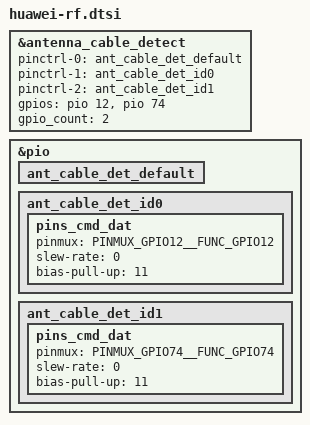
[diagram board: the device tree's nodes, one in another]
&antenna_cable_detect {
	pinctrl-names = "default", "id0", "id1";
	pinctrl-0 = <&ant_cable_det_default>;
	pinctrl-1 = <&ant_cable_det_id0>;
	pinctrl-2 = <&ant_cable_det_id1>;
	gpios = <&pio 12 0 >,
			<&pio 74 0 >;
	gpio_count = <2>;
};

&pio {
	ant_cable_det_default: ant_cable_det_default {
	};

	ant_cable_det_id0: ant_cable_det_id0 {
		pins_cmd_dat {
			pinmux = <PINMUX_GPIO12__FUNC_GPIO12>;
			slew-rate = <0>;
			bias-pull-up = <11>;
		};
	};
	ant_cable_det_id1: ant_cable_det_id1 {
		pins_cmd_dat {
			pinmux = <PINMUX_GPIO74__FUNC_GPIO74>;
			slew-rate = <0>;
			bias-pull-up = <11>;
		};
	};
};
